VERSION "HIPBNYYYYYYYYYYYYYYYYYYYYYYYYYYYYYYYYYYYYY/4/%%%/4/'%**4YYY///"

NS_ :

BS_:

BU_:

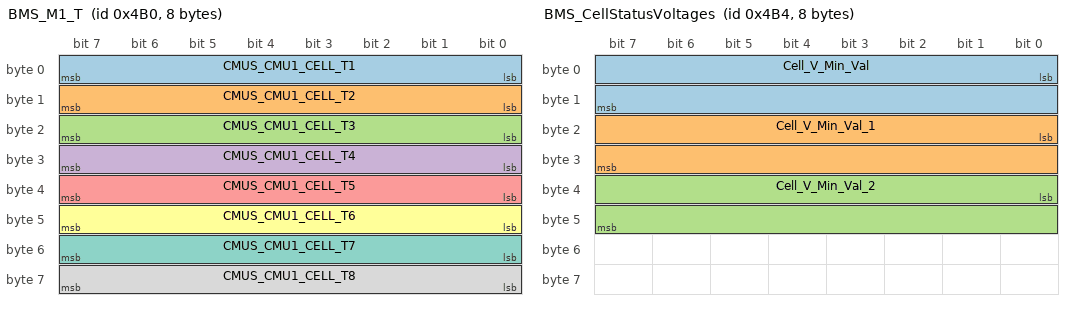
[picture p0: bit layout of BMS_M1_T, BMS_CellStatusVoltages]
BO_ 1200 BMS_M1_T: 8 Vector__XXX
 SG_ CMUS_CMU1_CELL_T1 : 0|8@1- (1,0) [0|0] "◦C" Vector__XXX
 SG_ CMUS_CMU1_CELL_T2 : 8|8@1- (1,0) [0|0] "◦C" Vector__XXX
 SG_ CMUS_CMU1_CELL_T3 : 16|8@1- (1,0) [0|0] "◦C" Vector__XXX
 SG_ CMUS_CMU1_CELL_T4 : 24|8@1- (1,0) [0|0] "◦C" Vector__XXX
 SG_ CMUS_CMU1_CELL_T5 : 32|8@1- (1,0) [0|0] "◦C" Vector__XXX
 SG_ CMUS_CMU1_CELL_T6 : 40|8@1- (1,0) [0|0] "◦C" Vector__XXX
 SG_ CMUS_CMU1_CELL_T7 : 48|8@1- (1,0) [0|0] "◦C" Vector__XXX
 SG_ CMUS_CMU1_CELL_T8 : 56|8@1- (1,0) [0|0] "◦C" Vector__XXX

BO_ 1204 BMS_CellStatusVoltages: 8 Vector__XXX
 SG_ Cell_V_Min_Val : 0|16@1+ (0.1,0) [0|0] "mV" Vector__XXX
 SG_ Cell_V_Min_Val_1 : 16|16@1+ (0.1,0) [0|0] "mV" Vector__XXX
 SG_ Cell_V_Min_Val_2 : 32|16@1+ (0.1,0) [0|0] "mV" Vector__XXX

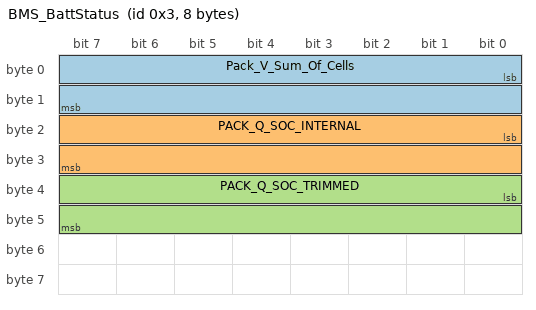
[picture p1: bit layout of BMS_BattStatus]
BO_ 3 BMS_BattStatus: 8 Vector__XXX
 SG_ Pack_V_Sum_Of_Cells : 0|16@1+ (0.1,0) [0|0] "V" Vector__XXX
 SG_ PACK_Q_SOC_INTERNAL : 16|16@1- (0.01,0) [0|0] "%" Vector__XXX
 SG_ PACK_Q_SOC_TRIMMED : 32|16@1+ (0.01,0) [0|0] "%" Vector__XXX

CM_ SG_ 3 Pack_V_Sum_Of_Cells "Sum of all cells";
CM_ SG_ 3 PACK_Q_SOC_INTERNAL "SoC";
CM_ SG_ 3 PACK_Q_SOC_TRIMMED "SoC";
BA_DEF_ BO_  "VFrameFormat" ENUM  "StandardCAN","ExtendedCAN","reserved","J1939PG","reserved","reserved","reserved","reserved","reserved","reserved","reserved","reserved","reserved","reserved","StandardCAN_FD","ExtendedCAN_FD";
BA_DEF_ BO_  "CANFD_BRS" ENUM  "0","1";
BA_DEF_DEF_  "VFrameFormat" "StandardCAN";
BA_DEF_DEF_  "CANFD_BRS" "0";
